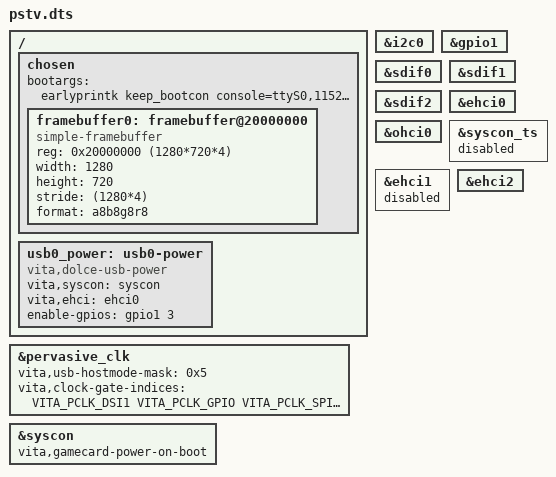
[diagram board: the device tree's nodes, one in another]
// SPDX-License-Identifier: GPL-2.0
/*
 * Device Tree Source for the PlayStation TV
 */

/dts-v1/;

#include <dt-bindings/gpio/gpio.h>
#include <dt-bindings/leds/common.h>
#include <dt-bindings/interrupt-controller/arm-gic.h>
#include <dt-bindings/clock/vita-pervasive.h>
#include "vita.dtsi"

/ {
	chosen {
		bootargs = "earlyprintk keep_bootcon console=ttyS0,115200 console=tty0";

		framebuffer0: framebuffer@20000000 {
			compatible = "simple-framebuffer";
			reg = <0x20000000 (1280*720*4)>;
		width = <1280>;
			height = <720>;
			stride = <(1280*4)>;
			format = "a8b8g8r8";
			status = "okay";
		};
	};
};

&i2c0 {
	status = "okay";
};

/* GPIO1 pin 3 is the external Type-A port's VBUS enable on this board. */
&gpio1 {
	status = "okay";
};

/* Bus 0 is the external Type-A port; bus 2 carries internal Realtek Ethernet.
 * Bus 1 has no identified PSTV attachment, and all-bus 0x7 remains unvalidated.
 */
&pervasive_clk {
	vita,usb-hostmode-mask = <0x5>;
	vita,clock-gate-indices = <VITA_PCLK_DSI1 VITA_PCLK_GPIO
				    VITA_PCLK_SPI0 VITA_PCLK_UART0
				    VITA_PCLK_MSIF>;
};

/* I2C1 has ADV7533 HDMI transmitter (0x38, 0x3D-0x3F) — disabled until
 * a driver is written. Also has motion sensor (0x0C) and LCD brightness (0x64). */

/* SDIF0 = eMMC, SDIF2 = WLAN/BT (SD8787 via SDIO) */
&sdif0 {
	status = "okay";
};

/* SDIF3 (microSD) disabled -- no card present, and polling creates log spam.
 *
 * SDIF1 (game card) is enabled for SD2Vita bring-up. Note that presence
 * detection is already bypassed: sdhci-vita sets
 * SDHCI_QUIRK_BROKEN_CARD_DETECTION for every SDIF host, so the MMC core
 * assumes a card is always present and polls. No non-removable / broken-cd /
 * pwrseq property is needed.
 *
 * The slot power rail (Ernie syscon 0x888, ksceSysconCtrlSdPower) is NOT
 * enabled here: our own reboot notifier powers it off and nothing turns it
 * back on. Use the gamecard_power sysfs attribute to power the rail and
 * rescan bus 1. See docs/plans/2026-09-12-sdif1-gamecard-bringup.md */
&sdif1 {
	status = "okay";
};

&sdif2 {
	status = "okay";
};

/* USB host (EHCI-only; see the OHCI note in vita.dtsi).  Bus 0 is the
 * external Type-A port and bus 2 carries the internal Realtek 0bda:8152
 * USB-Ethernet adapter; both were identified on hardware in 2026-08.  Bus 1
 * has no identified attachment and is deliberately disabled on PSTV.
 */
&ehci0 {
	status = "okay";
};

/*
 * Bus-zero full/low-speed companion.  Only the PSTV routes a physical
 * socket to it, and its driver defers until &ehci0 is bound and running.
 */
&ohci0 {
	status = "okay";
};

/* The game-card slot carries an SD2Vita on this unit. */
&syscon {
	vita,gamecard-power-on-boot;
};

/* The PSTV (Dolce) has no touch panel. Probing the syscon touchscreen
 * on it issues Ernie touch commands with no hardware behind them,
 * which wedges the console during boot (observed 2026-08-19, c17).
 */
&syscon_ts {
	status = "disabled";
};

&ehci1 {
	status = "disabled";
};

&ehci2 {
	status = "okay";
};

/ {
	/* The external Type-A socket is on Sony bus 0 (&ehci0).  It stays
	 * dead until both the Dolce 5 V rail and GPIO1 pin 3 are asserted,
	 * which this node's driver does once &ehci0 has finished probing.
	 */
	usb0_power: usb0-power {
		compatible = "vita,dolce-usb-power";
		vita,syscon = <&syscon>;
		vita,ehci = <&ehci0>;
		enable-gpios = <&gpio1 3 GPIO_ACTIVE_HIGH>;
	};
};
